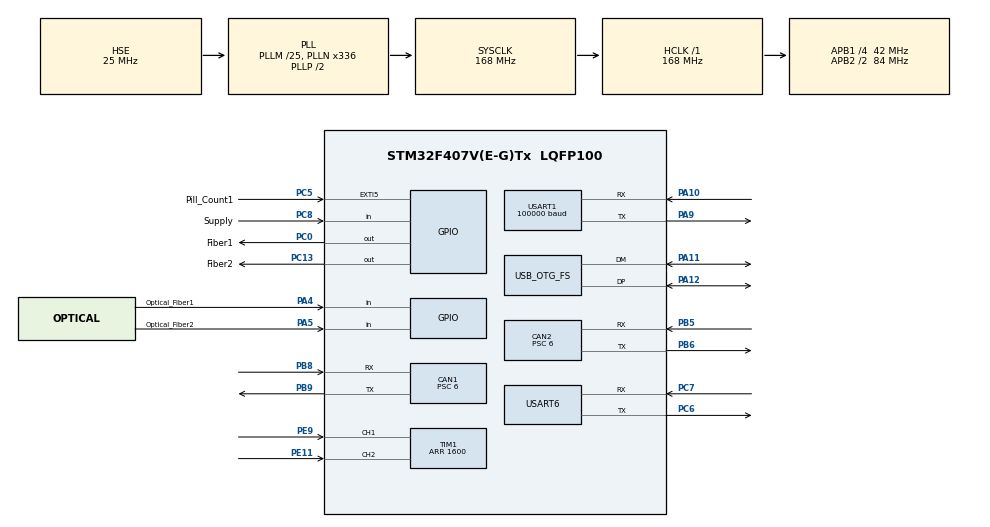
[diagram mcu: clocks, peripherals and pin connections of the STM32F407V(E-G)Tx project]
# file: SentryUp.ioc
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CAN1.BS1=CAN_BS1_3TQ
CAN1.BS2=CAN_BS2_3TQ
CAN1.CalculateBaudRate=1000000
CAN1.CalculateTimeBit=999.99
CAN1.CalculateTimeQuantum=142.85714285714286
CAN1.Prescaler=6
CAN2.BS1=CAN_BS1_3TQ
CAN2.BS2=CAN_BS2_3TQ
CAN2.CalculateBaudRate=1000000
CAN2.CalculateTimeBit=999.99
CAN2.CalculateTimeQuantum=142.85714285714286
CAN2.Prescaler=6
Dma.Request0=USART1_RX
Dma.Request1=USART6_RX
Dma.USART1_RX.0.Direction=DMA_PERIPH_TO_MEMORY
Dma.USART1_RX.0.FIFOMode=DMA_FIFOMODE_DISABLE
Dma.USART1_RX.0.Instance=DMA2_Stream2
Dma.USART1_RX.0.MemDataAlignment=DMA_MDATAALIGN_BYTE
Dma.USART1_RX.0.MemInc=DMA_MINC_ENABLE
Dma.USART1_RX.0.Mode=DMA_NORMAL
Dma.USART1_RX.0.PeriphDataAlignment=DMA_PDATAALIGN_BYTE
Dma.USART1_RX.0.PeriphInc=DMA_PINC_DISABLE
Dma.USART1_RX.0.Priority=DMA_PRIORITY_LOW
Dma.USART6_RX.1.Direction=DMA_PERIPH_TO_MEMORY
Dma.USART6_RX.1.FIFOMode=DMA_FIFOMODE_DISABLE
Dma.USART6_RX.1.Instance=DMA2_Stream1
Dma.USART6_RX.1.MemDataAlignment=DMA_MDATAALIGN_BYTE
Dma.USART6_RX.1.MemInc=DMA_MINC_ENABLE
Dma.USART6_RX.1.Mode=DMA_NORMAL
Dma.USART6_RX.1.PeriphDataAlignment=DMA_PDATAALIGN_BYTE
Dma.USART6_RX.1.PeriphInc=DMA_PINC_DISABLE
Dma.USART6_RX.1.Priority=DMA_PRIORITY_LOW
FREERTOS.INCLUDE_vTaskDelayUntil=1
FREERTOS.Tasks01=defaultTask,0,128,StartDefaultTask,Default,NULL,Dynamic,NULL,NULL
Mcu.Family=STM32F4
Mcu.Name=STM32F407V(E-G)Tx
Mcu.Package=LQFP100
NVIC.CAN1_RX0_IRQn=true\:1\:0\:true\:false\:true\:false\:true\:true
NVIC.CAN2_RX1_IRQn=true\:5\:0\:false\:false\:true\:true\:true\:true
NVIC.DMA2_Stream1_IRQn=true\:5\:0\:true\:false\:true\:true\:false\:true
NVIC.DMA2_Stream2_IRQn=true\:5\:0\:false\:false\:true\:true\:false\:true
NVIC.EXTI9_5_IRQn=true\:7\:0\:true\:false\:true\:true\:true\:true
NVIC.OTG_FS_IRQn=true\:5\:0\:false\:false\:true\:true\:false\:true
NVIC.PriorityGroup=NVIC_PRIORITYGROUP_4
NVIC.TIM1_UP_TIM10_IRQn=true\:7\:0\:true\:false\:true\:true\:true\:true
NVIC.USART1_IRQn=true\:6\:0\:true\:false\:true\:true\:true\:true
PA10.Mode=Asynchronous
PA10.Signal=USART1_RX
PA11.Mode=Device_Only
PA11.Signal=USB_OTG_FS_DM
PA12.Mode=Device_Only
PA12.Signal=USB_OTG_FS_DP
PA13.Mode=Serial_Wire
PA13.Signal=SYS_JTMS-SWDIO
PA14.Mode=Serial_Wire
PA14.Signal=SYS_JTCK-SWCLK
PA4.GPIO_Label=Optical_Fiber1
PA4.GPIO_Mode=GPIO_MODE_INPUT
PA4.GPIO_PuPd=GPIO_PULLUP
PA4.Signal=GPIO_Input
PA5.GPIO_Label=Optical_Fiber2
PA5.GPIO_Mode=GPIO_MODE_INPUT
PA5.GPIO_PuPd=GPIO_PULLUP
PA5.Signal=GPIO_Input
PA9.Mode=Asynchronous
PA9.Signal=USART1_TX
PB5.Mode=CAN_Activate
PB5.Signal=CAN2_RX
PB6.Mode=CAN_Activate
PB6.Signal=CAN2_TX
PB8.Mode=CAN_Activate
PB8.Signal=CAN1_RX
PB9.Mode=CAN_Activate
PB9.Signal=CAN1_TX
PC0.GPIO_Label=Fiber1
PC0.GPIO_ModeDefaultOutputPP=GPIO_MODE_OUTPUT_OD
PC0.GPIO_PuPd=GPIO_NOPULL
PC0.PinState=GPIO_PIN_SET
PC0.Signal=GPIO_Output
PC13-ANTI_TAMP.GPIO_Label=Fiber2
PC13-ANTI_TAMP.GPIO_ModeDefaultOutputPP=GPIO_MODE_OUTPUT_OD
PC13-ANTI_TAMP.GPIO_PuPd=GPIO_NOPULL
PC13-ANTI_TAMP.PinState=GPIO_PIN_SET
PC13-ANTI_TAMP.Signal=GPIO_Output
PC5.GPIO_Label=Pill_Count1
PC5.GPIO_ModeDefaultEXTI=GPIO_MODE_IT_FALLING
PC5.GPIO_PuPd=GPIO_PULLUP
PC5.Signal=GPXTI5
PC6.Mode=Asynchronous
PC6.Signal=USART6_TX
PC7.Mode=Asynchronous
PC7.Signal=USART6_RX
PC8.GPIO_Label=Supply
PC8.GPIO_PuPd=GPIO_PULLUP
PC8.Signal=GPIO_Input
PE11.GPIO_PuPd=GPIO_PULLUP
PE11.Signal=S_TIM1_CH2
PE9.GPIO_PuPd=GPIO_PULLUP
PE9.Signal=S_TIM1_CH1
PH0-OSC_IN.Mode=HSE-External-Oscillator
PH0-OSC_IN.Signal=RCC_OSC_IN
PH1-OSC_OUT.Mode=HSE-External-Oscillator
PH1-OSC_OUT.Signal=RCC_OSC_OUT
ProjectManager.HeapSize=0x800
ProjectManager.StackSize=0x1000
ProjectManager.TargetToolchain=MDK-ARM V5.27
RCC.48MHZClocksFreq_Value=48000000
RCC.AHBFreq_Value=168000000
RCC.APB1CLKDivider=RCC_HCLK_DIV4
RCC.APB1Freq_Value=42000000
RCC.APB1TimFreq_Value=84000000
RCC.APB2CLKDivider=RCC_HCLK_DIV2
RCC.APB2Freq_Value=84000000
RCC.APB2TimFreq_Value=168000000
RCC.CortexFreq_Value=168000000
RCC.HCLKFreq_Value=168000000
RCC.HSE_VALUE=25000000
RCC.HSI_VALUE=16000000
RCC.LSE_VALUE=32768
RCC.PLLM=25
RCC.PLLN=336
RCC.PLLQ=7
RCC.SYSCLKFreq_VALUE=168000000
RCC.SYSCLKSource=RCC_SYSCLKSOURCE_PLLCLK
RCC.VCOOutputFreq_Value=336000000
SH.S_TIM1_CH1.0=TIM1_CH1,Encoder_Interface
SH.S_TIM1_CH2.0=TIM1_CH2,Encoder_Interface
TIM1.EncoderMode=TIM_ENCODERMODE_TI12
TIM1.Period=1600
TIM2.AutoReloadPreload=TIM_AUTORELOAD_PRELOAD_ENABLE
TIM2.Period=0xFFFFFFFF
TIM2.Prescaler=839
USART1.BaudRate=100000
USART1.VirtualMode=VM_ASYNC
USART6.VirtualMode=VM_ASYNC
USB_DEVICE.CLASS_NAME_FS=CDC
USB_DEVICE.VirtualMode-CDC_FS=Cdc
USB_DEVICE.VirtualModeFS=Cdc_FS
USB_OTG_FS.VirtualMode=Device_Only
VP_FREERTOS_VS_CMSIS_V1.Mode=CMSIS_V1
VP_TIM2_VS_ClockSourceINT.Mode=Internal
VP_USB_DEVICE_VS_USB_DEVICE_CDC_FS.Mode=CDC_FS
board=custom

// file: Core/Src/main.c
/* USER CODE BEGIN Header */
/**
  ******************************************************************************
  * @file           : main.c
  * @brief          : Main program body
  ******************************************************************************
  * @attention
  *
  * <h2><center>&copy; Copyright (c) 2021 STMicroelectronics.
  * All rights reserved.</center></h2>
  *
  * This software component is licensed by ST under Ultimate Liberty license
  * SLA0044, the "License"; You may not use this file except in compliance with
  * the License. You may obtain a copy of the License at:
  *                             www.st.com/SLA0044
  *
  ******************************************************************************
  */
/* USER CODE END Header */
#include "main.h"
#include "cmsis_os.h"
#include "can.h"
#include "dma.h"
#include "tim.h"
#include "usart.h"
#include "usb_device.h"
#include "gpio.h"

void SystemClock_Config(void);
void MX_FREERTOS_Init(void);

int main(void)
{

  /* MCU Configuration--------------------------------------------------------*/

  /* Reset of all peripherals, Initializes the Flash interface and the Systick. */
  HAL_Init();

  /* Configure the system clock */
  SystemClock_Config();

  /* Initialize all configured peripherals */
  MX_GPIO_Init();
  MX_DMA_Init();
  MX_CAN1_Init();
  MX_TIM2_Init();
  MX_USART1_UART_Init();
  MX_CAN2_Init();
  MX_TIM1_Init();
  MX_USART6_UART_Init();

  /* Call init function for freertos objects (in freertos.c) */
  MX_FREERTOS_Init();
  /* Start scheduler */
  osKernelStart();

  /* We should never get here as control is now taken by the scheduler */
  /* Infinite loop */
  while (1)
  {

  }
}

void SystemClock_Config(void)
{
  RCC_OscInitTypeDef RCC_OscInitStruct = {0};
  RCC_ClkInitTypeDef RCC_ClkInitStruct = {0};

  /** Configure the main internal regulator output voltage
  */
  __HAL_RCC_PWR_CLK_ENABLE();
  __HAL_PWR_VOLTAGESCALING_CONFIG(PWR_REGULATOR_VOLTAGE_SCALE1);
  /** Initializes the RCC Oscillators according to the specified parameters
  * in the RCC_OscInitTypeDef structure.
  */
  RCC_OscInitStruct.OscillatorType = RCC_OSCILLATORTYPE_HSE;
  RCC_OscInitStruct.HSEState = RCC_HSE_ON;
  RCC_OscInitStruct.PLL.PLLState = RCC_PLL_ON;
  RCC_OscInitStruct.PLL.PLLSource = RCC_PLLSOURCE_HSE;
  RCC_OscInitStruct.PLL.PLLM = 25;
  RCC_OscInitStruct.PLL.PLLN = 336;
  RCC_OscInitStruct.PLL.PLLP = RCC_PLLP_DIV2;
  RCC_OscInitStruct.PLL.PLLQ = 7;
  if (HAL_RCC_OscConfig(&RCC_OscInitStruct) != HAL_OK)
  {
    Error_Handler();
  }
  /** Initializes the CPU, AHB and APB buses clocks
  */
  RCC_ClkInitStruct.ClockType = RCC_CLOCKTYPE_HCLK|RCC_CLOCKTYPE_SYSCLK
                              |RCC_CLOCKTYPE_PCLK1|RCC_CLOCKTYPE_PCLK2;
  RCC_ClkInitStruct.SYSCLKSource = RCC_SYSCLKSOURCE_PLLCLK;
  RCC_ClkInitStruct.AHBCLKDivider = RCC_SYSCLK_DIV1;
  RCC_ClkInitStruct.APB1CLKDivider = RCC_HCLK_DIV4;
  RCC_ClkInitStruct.APB2CLKDivider = RCC_HCLK_DIV2;

  if (HAL_RCC_ClockConfig(&RCC_ClkInitStruct, FLASH_LATENCY_5) != HAL_OK)
  {
    Error_Handler();
  }
}

void Error_Handler(void)
{
  __disable_irq();
  while (1)
  {
  }
}

/************************ (C) COPYRIGHT STMicroelectronics *****END OF FILE****/

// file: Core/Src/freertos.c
/* USER CODE BEGIN Header */
/**
  ******************************************************************************
  * File Name          : freertos.c
  * Description        : Code for freertos applications
  ******************************************************************************
  * @attention
  *
  * <h2><center>&copy; Copyright (c) 2021 STMicroelectronics.
  * All rights reserved.</center></h2>
  *
  * This software component is licensed by ST under Ultimate Liberty license
  * SLA0044, the "License"; You may not use this file except in compliance with
  * the License. You may obtain a copy of the License at:
  *                             www.st.com/SLA0044
  *
  ******************************************************************************
  */
/* USER CODE END Header */

#include "FreeRTOS.h"
#include "task.h"
#include "main.h"
#include "cmsis_os.h"

/* USER CODE BEGIN Includes */
#include "FreeRTOS_Task.h"
/* USER CODE END Includes */

osThreadId defaultTaskHandle;

void StartDefaultTask(void const * argument);

extern void MX_USB_DEVICE_Init(void);
void MX_FREERTOS_Init(void); /* (MISRA C 2004 rule 8.1) */

/* GetIdleTaskMemory prototype (linked to static allocation support) */
void vApplicationGetIdleTaskMemory( StaticTask_t **ppxIdleTaskTCBBuffer, StackType_t **ppxIdleTaskStackBuffer, uint32_t *pulIdleTaskStackSize );

/* USER CODE BEGIN GET_IDLE_TASK_MEMORY */
static StaticTask_t xIdleTaskTCBBuffer;
static StackType_t xIdleStack[configMINIMAL_STACK_SIZE];

void vApplicationGetIdleTaskMemory( StaticTask_t **ppxIdleTaskTCBBuffer, StackType_t **ppxIdleTaskStackBuffer, uint32_t *pulIdleTaskStackSize )
{
  *ppxIdleTaskTCBBuffer = &xIdleTaskTCBBuffer;
  *ppxIdleTaskStackBuffer = &xIdleStack[0];
  *pulIdleTaskStackSize = configMINIMAL_STACK_SIZE;
  /* place for user code */
}
/* USER CODE END GET_IDLE_TASK_MEMORY */

void MX_FREERTOS_Init(void) {

  /* Create the thread(s) */
  /* definition and creation of defaultTask */
  osThreadDef(defaultTask, StartDefaultTask, osPriorityNormal, 0, 128);
  defaultTaskHandle = osThreadCreate(osThread(defaultTask), NULL);

}

void StartDefaultTask(void const * argument)
{
  /* init code for USB_DEVICE */
  MX_USB_DEVICE_Init();
  /* USER CODE BEGIN StartDefaultTask */
    vPortEnterCritical();
    StartTask();
    vPortExitCritical();
    vTaskDelete(NULL);
  /* Infinite loop */
  for(;;)
  {
    osDelay(1);
  }
  /* USER CODE END StartDefaultTask */
}

/************************ (C) COPYRIGHT STMicroelectronics *****END OF FILE****/
